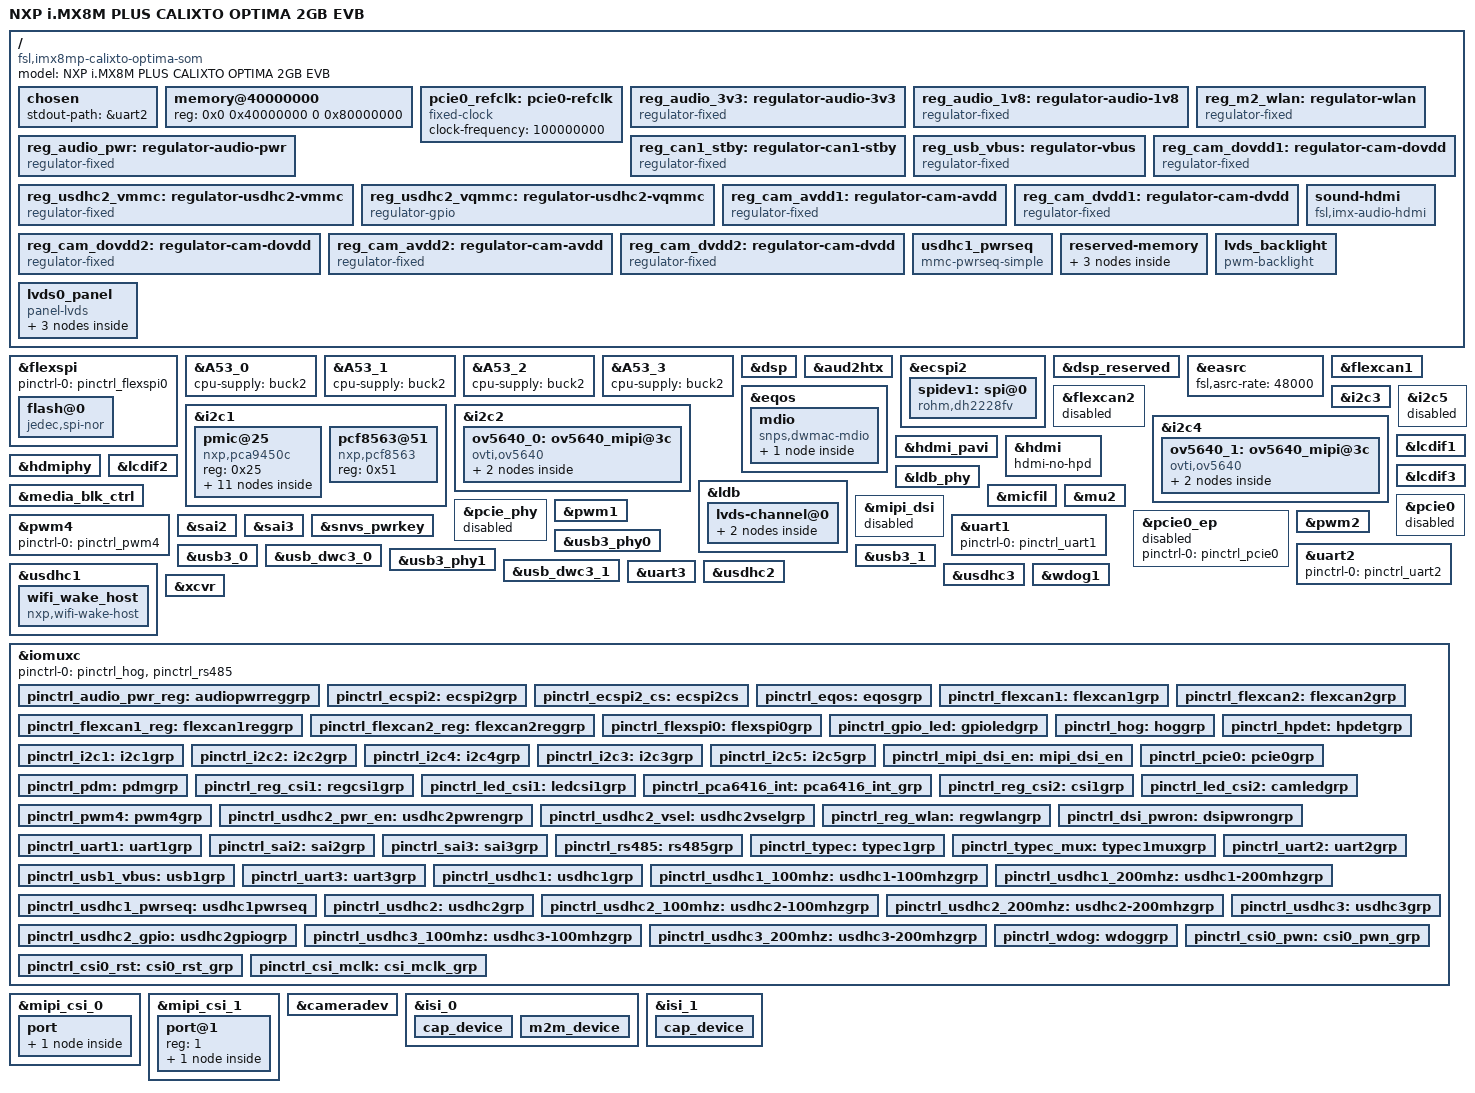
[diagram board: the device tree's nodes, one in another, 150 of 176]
// SPDX-License-Identifier: (GPL-2.0+ OR MIT)
/*
 * Copyright 2019 NXP
 */

/dts-v1/;

#include <dt-bindings/phy/phy-imx8-pcie.h>
#include <dt-bindings/usb/pd.h>
#include "imx8mp.dtsi"
#include "imx8mp-nxp-display.dtsi"
#include "imx8mp-nxp-capture.dtsi"

/ {
	model = "NXP i.MX8M PLUS CALIXTO OPTIMA 2GB EVB";
	compatible = "fsl,imx8mp-calixto-optima-som", "fsl,imx8mp";

	chosen {
		stdout-path = &uart2;
	};

	memory@40000000 {
		device_type = "memory";
		reg = <0x0 0x40000000 0 0x80000000>;
	};

	pcie0_refclk: pcie0-refclk {
		compatible = "fixed-clock";
		#clock-cells = <0>;
		clock-frequency = <100000000>;
	};

	reg_audio_3v3: regulator-audio-3v3 {
		compatible = "regulator-fixed";
		regulator-name = "audio-3v3";
		regulator-min-microvolt = <3300000>;
		regulator-max-microvolt = <3300000>;
		regulator-always-on;
		regulator-boot-on;
	};

	reg_audio_1v8: regulator-audio-1v8 {
		compatible = "regulator-fixed";
		regulator-name = "audio-1v8";
		regulator-min-microvolt = <1800000>;
		regulator-max-microvolt = <1800000>;
		regulator-always-on;
		regulator-boot-on;
	};

	reg_audio_pwr: regulator-audio-pwr {
		compatible = "regulator-fixed";
		regulator-name = "audio-pwr";
		regulator-min-microvolt = <3300000>;
		regulator-max-microvolt = <3300000>;
		regulator-always-on;
		regulator-boot-on;
	};

	reg_can1_stby: regulator-can1-stby {
		compatible = "regulator-fixed";
		regulator-name = "can1-stby";
		regulator-min-microvolt = <3300000>;
		regulator-max-microvolt = <3300000>;
		regulator-always-on;
		regulator-boot-on;
	};

	reg_m2_wlan: regulator-wlan {
		compatible = "regulator-fixed";
		regulator-name = "WLAN_EN";
		regulator-min-microvolt = <3300000>;
		regulator-max-microvolt = <3300000>;
		regulator-always-on;
		regulator-boot-on;
	};

	reg_usb_vbus: regulator-vbus {
		compatible = "regulator-fixed";
		regulator-name = "USB_VBUS";
		regulator-min-microvolt = <5000000>;
		regulator-max-microvolt = <5000000>;
		regulator-always-on;		
		regulator-boot-on;
	};
	
	reg_usdhc2_vmmc: regulator-usdhc2-vmmc {
		compatible = "regulator-fixed";
		pinctrl-names = "default";
		pinctrl-0 = <&pinctrl_usdhc2_pwr_en>;
		gpios = <&gpio2 19 GPIO_ACTIVE_HIGH>;
		enable-active-high;
		off-on-delay-us = <100000>;
		regulator-always-on;
		regulator-max-microvolt = <3300000>;
		regulator-min-microvolt = <3300000>;
		regulator-name = "3V3_SD";
		startup-delay-us = <20000>;
	};

	reg_usdhc2_vqmmc: regulator-usdhc2-vqmmc {
		compatible = "regulator-gpio";
		pinctrl-names = "default";
		pinctrl-0 = <&pinctrl_usdhc2_vsel>;
		gpios = <&gpio1 4 GPIO_ACTIVE_HIGH>;
		regulator-max-microvolt = <3300000>;
		regulator-min-microvolt = <1800000>;
		regulator-always-on;
		states = <1800000 0x1>,
			 <3300000 0x0>;
		regulator-name = "PMIC_USDHC_VSELECT";
		vin-supply = <&ldo5>;
	};
	
	reg_cam_dovdd1: regulator-cam-dovdd {
		compatible = "regulator-fixed";
		pinctrl-names = "default";
		pinctrl-0 = <&pinctrl_reg_csi1>;
		regulator-name = "CAM_DOVDD";
		regulator-min-microvolt = <3000000>;
		regulator-max-microvolt = <3000000>;
		gpio = <&gpio1 3 GPIO_ACTIVE_HIGH>;
		enable-active-high;
	};
	
	reg_cam_avdd1: regulator-cam-avdd {
		compatible = "regulator-fixed";
		regulator-name = "CAM_AVDD";
		regulator-min-microvolt = <2800000>;
		regulator-max-microvolt = <2800000>;
		gpio = <&gpio1 3 GPIO_ACTIVE_HIGH>;
		enable-active-high;
	};
	
	reg_cam_dvdd1: regulator-cam-dvdd {
		compatible = "regulator-fixed";
		regulator-name = "CAM_DVDD";
		regulator-min-microvolt = <1500000>;
		regulator-max-microvolt = <1500000>;
		gpio = <&gpio1 3 GPIO_ACTIVE_HIGH>;
		enable-active-high;
	};

	reg_cam_dovdd2: regulator-cam-dovdd {
		compatible = "regulator-fixed";
		pinctrl-names = "default";
		pinctrl-0 = <&pinctrl_reg_csi1>;
		regulator-name = "CAM_DOVDD";
		regulator-min-microvolt = <3000000>;
		regulator-max-microvolt = <3000000>;
		gpio = <&gpio1 11 GPIO_ACTIVE_HIGH>;
		enable-active-high;
	};
	
	reg_cam_avdd2: regulator-cam-avdd {
		compatible = "regulator-fixed";
		regulator-name = "CAM_AVDD";
		regulator-min-microvolt = <2800000>;
		regulator-max-microvolt = <2800000>;
		gpio = <&gpio1 11 GPIO_ACTIVE_HIGH>;
		enable-active-high;
	};
	
	reg_cam_dvdd2: regulator-cam-dvdd {
		compatible = "regulator-fixed";
		regulator-name = "CAM_DVDD";
		regulator-min-microvolt = <1500000>;
		regulator-max-microvolt = <1500000>;
		gpio = <&gpio1 11 GPIO_ACTIVE_HIGH>;
		enable-active-high;
	};
	
	sound-hdmi {
		compatible = "fsl,imx-audio-hdmi";
		model = "audio-hdmi";
		audio-cpu = <&aud2htx>;
		hdmi-out;
	};

	usdhc1_pwrseq: usdhc1_pwrseq {
		compatible = "mmc-pwrseq-simple";
		pinctrl-names = "default";
		pinctrl-0 = <&pinctrl_usdhc1_pwrseq>;
		reset-gpios = <&gpio2 10 GPIO_ACTIVE_LOW>;
	};

	reserved-memory {
		#address-cells = <2>;
		#size-cells = <2>;
		ranges;

		dsp_vdev0vring0: vdev0vring0@942f0000 {
			reg = <0 0x942f0000 0 0x8000>;
			no-map;
		};

		dsp_vdev0vring1: vdev0vring1@942f8000 {
			reg = <0 0x942f8000 0 0x8000>;
			no-map;
		};

		dsp_vdev0buffer: vdev0buffer@94300000 {
			compatible = "shared-dma-pool";
			reg = <0 0x94300000 0 0x100000>;
			no-map;
		};
	};

	lvds_backlight: lvds_backlight {
		compatible = "pwm-backlight";
		pwms = <&pwm1 0 100000 0>;
		status = "okay";

		brightness-levels = < 0  1  2  3  4  5  6  7  8  9
				     10 11 12 13 14 15 16 17 18 19
				     20 21 22 23 24 25 26 27 28 29
				     30 31 32 33 34 35 36 37 38 39
				     40 41 42 43 44 45 46 47 48 49
				     50 51 52 53 54 55 56 57 58 59
				     60 61 62 63 64 65 66 67 68 69
				     70 71 72 73 74 75 76 77 78 79
				     80 81 82 83 84 85 86 87 88 89
				     90 91 92 93 94 95 96 97 98 99
				    100>;
		default-brightness-level = <80>;
	};
	
	lvds0_panel {
		status = "okay";
		backlight = <&lvds_backlight>;
		compatible = "panel-lvds"; 
		data-mapping = "vesa-24";
		//enable-gpios = <&gpio2 26 GPIO_ACTIVE_HIGH>;
		width-mm = <124>;
		height-mm = <80>;

		panel-timing {
			clock-frequency = <25000000>;
			hactive = <800>;
			vactive = <480>;
			hfront-porch = <8>;
			hback-porch = <8>;
			hsync-len = <4>;
			vback-porch = <8>;
			vfront-porch = <8>;
			vsync-len = <4>;
			hsync-active = <0>;
			vsync-active = <0>;
			de-active = <1>;
                	pixelclk-active = <0>;
		};

		port {
			panel_lvds_in: endpoint {
				remote-endpoint = <&lvds_out>;
			};
		};
	};
	
};

&flexspi {
	pinctrl-names = "default";
	pinctrl-0 = <&pinctrl_flexspi0>;
	status = "okay";

	flash@0 {
		compatible = "jedec,spi-nor";
		reg = <0>;
		spi-max-frequency = <80000000>;
		spi-tx-bus-width = <1>;
		spi-rx-bus-width = <4>;
	};
};

&A53_0 {
	cpu-supply = <&buck2>;
};

&A53_1 {
	cpu-supply = <&buck2>;
};

&A53_2 {
	cpu-supply = <&buck2>;
};

&A53_3 {
	cpu-supply = <&buck2>;
};

&dsp {
	status = "okay";
};

&aud2htx {
	status = "okay";
};

&ecspi2 {
	#address-cells = <1>;
	#size-cells = <0>;
	pinctrl-names = "default";
	pinctrl-0 = <&pinctrl_ecspi2 &pinctrl_ecspi2_cs>;
	cs-gpios = <&gpio5 13 GPIO_ACTIVE_LOW>;
	status = "okay";

	spidev1: spi@0 {
		reg = <0>;
		compatible = "rohm,dh2228fv";
		spi-max-frequency = <500000>;
	};
};

&dsp_reserved {
	status = "okay";
};

&dsp {
	memory-region = <&dsp_vdev0buffer>, <&dsp_vdev0vring0>,
			<&dsp_vdev0vring1>, <&dsp_reserved>;
	status = "okay";
};

&easrc {
	fsl,asrc-rate = <48000>;
	status = "okay";
};

&eqos {
	pinctrl-names = "default";
	pinctrl-0 = <&pinctrl_eqos>;
	phy-mode = "rgmii-id";
	phy-handle = <&ethphy0>;
	status = "okay";

	mdio {
		compatible = "snps,dwmac-mdio";
		#address-cells = <1>;
		#size-cells = <0>;

		ethphy0: ethernet-phy@6 {
			compatible = "ethernet-phy-ieee802.3-c22";
			reg = <6>;
			//reset-gpios = <&gpio4 22 GPIO_ACTIVE_LOW>;
			reset-assert-us = <10000>;
			reset-deassert-us = <80000>;
			//realtek,clkout-disable;
		};
	};

};

&flexcan1 {
	pinctrl-names = "default";
	pinctrl-0 = <&pinctrl_flexcan1>;
	xceiver-supply = <&reg_can1_stby>;
	status = "okay";
};

&flexcan2 {
	status = "disabled";/* can2 pin conflict with pdm */
};

&i2c1 {
	clock-frequency = <400000>;
	pinctrl-names = "default";
	pinctrl-0 = <&pinctrl_i2c1>;
	status = "okay";

	pmic@25 {
		compatible = "nxp,pca9450c";
		reg = <0x25>;

		regulators {
			buck1: BUCK1 {
				regulator-name = "BUCK1";
				regulator-min-microvolt = <600000>;
				regulator-max-microvolt = <2187500>;
				regulator-boot-on;
				regulator-always-on;
				regulator-ramp-delay = <3125>;
			};

			buck2: BUCK2 {
				regulator-name = "BUCK2";
				regulator-min-microvolt = <600000>;
				regulator-max-microvolt = <2187500>;
				regulator-boot-on;
				regulator-always-on;
				regulator-ramp-delay = <3125>;
				nxp,dvs-run-voltage = <950000>;
				nxp,dvs-standby-voltage = <850000>;
			};

			buck4: BUCK4{
				regulator-name = "BUCK4";
				regulator-min-microvolt = <600000>;
				regulator-max-microvolt = <3400000>;
				regulator-boot-on;
				regulator-always-on;
			};

			buck5: BUCK5{
				regulator-name = "BUCK5";
				regulator-min-microvolt = <600000>;
				regulator-max-microvolt = <3400000>;
				regulator-boot-on;
				regulator-always-on;
			};

			buck6: BUCK6 {
				regulator-name = "BUCK6";
				regulator-min-microvolt = <600000>;
				regulator-max-microvolt = <3400000>;
				regulator-boot-on;
				regulator-always-on;
			};

			ldo1: LDO1 {
				regulator-name = "LDO1";
				regulator-min-microvolt = <1600000>;
				regulator-max-microvolt = <3300000>;
				regulator-boot-on;
				regulator-always-on;
			};

			ldo2: LDO2 {
				regulator-name = "LDO2";
				regulator-min-microvolt = <800000>;
				regulator-max-microvolt = <1150000>;
				regulator-boot-on;
				regulator-always-on;
			};

			ldo3: LDO3 {
				regulator-name = "LDO3";
				regulator-min-microvolt = <800000>;
				regulator-max-microvolt = <3300000>;
				regulator-boot-on;
				regulator-always-on;
			};

			ldo4: LDO4 {
				regulator-name = "LDO4";
				regulator-min-microvolt = <800000>;
				regulator-max-microvolt = <3300000>;
				regulator-boot-on;
				regulator-always-on;
			};

			ldo5: LDO5 {
				regulator-name = "LDO5";
				regulator-min-microvolt = <1800000>;
				regulator-max-microvolt = <3300000>;
				regulator-boot-on;
				regulator-always-on;
			};
		};
	};
	
	pcf8563@51 {
		compatible = "nxp,pcf8563";
		reg = <0x51>;
	};
};

&i2c2 {
	clock-frequency = <400000>;
	pinctrl-names = "default";
	pinctrl-0 = <&pinctrl_i2c2>;
	status = "okay";

	ov5640_0: ov5640_mipi@3c {
		compatible = "ovti,ov5640";
		reg = <0x3c>;
		pinctrl-names = "default";
		pinctrl-0 = <&pinctrl_led_csi1>;
		DOVDD-supply = <&reg_cam_dovdd1>; /* 3.0v */
              	AVDD-supply = <&reg_cam_avdd1>;  /* 2.8v */
              	DVDD-supply = <&reg_cam_dvdd1>;  /* 1.5v */
		clocks = <&clk IMX8MP_CLK_IPP_DO_CLKO2>;
		clock-names = "xclk";
		assigned-clocks = <&clk IMX8MP_CLK_IPP_DO_CLKO2>;
		assigned-clock-parents = <&clk IMX8MP_CLK_24M>;
		assigned-clock-rates = <24000000>;
		status = "okay";

		port {
			ov5640_mipi_0_ep: endpoint {
				remote-endpoint = <&mipi_csi0_ep>;
				data-lanes = <1 2>;
				clock-lanes = <0>;
			};
		};
	};

};

&i2c3 {
	clock-frequency = <400000>;
	pinctrl-names = "default";
	pinctrl-0 = <&pinctrl_i2c3>;
	status = "okay";

};

/* I2C on expansion connector J22. */
&i2c5 {
	clock-frequency = <100000>; /* Lower clock speed for external bus. */
	pinctrl-names = "default";
	pinctrl-0 = <&pinctrl_i2c5>;
	status = "disabled"; /* can1 pins conflict with i2c5 */

	/* GPIO 2 of PCA6416 is used to switch between CAN1 and I2C5 functions:
	 *     LOW:  CAN1 (default, pull-down)
	 *     HIGH: I2C5
	 * You need to set it to high to enable I2C5 (for example, add gpio-hog
	 * in pca6416 node).
	 */
};

&i2c4 {

	clock-frequency = <400000>;
	pinctrl-names = "default";
	pinctrl-0 = <&pinctrl_i2c4>;
	status = "okay";

	ov5640_1: ov5640_mipi@3c {
		compatible = "ovti,ov5640";
		reg = <0x3c>;
		pinctrl-names = "default";
		pinctrl-0 = <&pinctrl_led_csi2>;
		DOVDD-supply = <&reg_cam_dovdd2>; /* 3.0v */
              	AVDD-supply = <&reg_cam_avdd2>;  /* 2.8v */
              	DVDD-supply = <&reg_cam_dvdd2>;  /* 1.5v */
		clocks = <&clk IMX8MP_CLK_IPP_DO_CLKO2>;
		clock-names = "xclk";
		assigned-clocks = <&clk IMX8MP_CLK_IPP_DO_CLKO2>;
		assigned-clock-parents = <&clk IMX8MP_CLK_24M>;
		assigned-clock-rates = <24000000>;
		csi_id = <0>;
		mclk = <24000000>;
		mclk_source = <0>;
		mipi_csi;
		status = "okay";

		port {
			ov5640_mipi_1_ep: endpoint {
				remote-endpoint = <&mipi_csi1_ep>;
				data-lanes = <1 2>;
				clock-lanes = <0>;
			};
		};
	};
	
};

&hdmi_pavi {
	status = "okay";
};

&hdmi {
	status = "okay";
	hdmi-no-hpd;
};

&hdmiphy {
	status = "okay";
};

&lcdif1 {
	status = "okay";
};

&lcdif2 {
	status = "okay";
};

&lcdif3 {
	status = "okay";

	thres-low  = <1 2>;             /* (FIFO * 1 / 2) */
	thres-high = <3 4>;             /* (FIFO * 3 / 4) */
};

&ldb {
	status = "okay";
	
	lvds-channel@0 {
		#address-cells = <1>;
		#size-cells = <0>;
		fsl,data-mapping = "spwg";
		fsl,data-width = <24>;
		status = "okay";

		port@1 {
			reg = <1>;
			lvds_out: endpoint {
				remote-endpoint = <&panel_lvds_in>;
			};
		};
	};
};

&ldb_phy {
	status = "okay";
};

&media_blk_ctrl {
       assigned-clock-rates = <500000000>, <200000000>,
                              <0>, <0>, <497700000>; // 71.1MHz
                               //<0>, <0>, <358400000>; // 51.2MHz
                              //<0>, <0>, <454970880>; // 64.9Mhz
};

&micfil {
	#sound-dai-cells = <0>;
	pinctrl-names = "default";
	pinctrl-0 = <&pinctrl_pdm>;
	assigned-clocks = <&clk IMX8MP_CLK_PDM>;
	assigned-clock-parents = <&clk IMX8MP_AUDIO_PLL1_OUT>;
	assigned-clock-rates = <196608000>;
	status = "okay";
};

&mipi_dsi {
	#address-cells = <1>;
	#size-cells = <0>;
	status = "disabled";
};

&mu2 {
	status = "okay";
};

&pcie_phy {
	fsl,refclk-pad-mode = <IMX8_PCIE_REFCLK_PAD_INPUT>;
	clocks = <&pcie0_refclk>;
	clock-names = "ref";
	status = "disabled";
};

&pcie0 {
	pinctrl-names = "default";
	pinctrl-0 = <&pinctrl_pcie0>;
	reset-gpio = <&gpio2 7 GPIO_ACTIVE_LOW>;
	host-wake-gpio = <&gpio5 21 GPIO_ACTIVE_LOW>;
	vpcie-supply = <&reg_m2_wlan>;
	supports-clkreq;
	status = "disabled";
};

&pcie0_ep {
	pinctrl-0 = <&pinctrl_pcie0>;
	pinctrl-names = "default";
	status = "disabled";
};

&pwm1 {
	//pinctrl-names = "default";
	//pinctrl-0 = <&pinctrl_pwm1>;
	status = "okay";
};

&pwm2 {
	//pinctrl-names = "default";
	//pinctrl-0 = <&pinctrl_pwm2>;
	status = "okay";
};

&pwm4 {
	pinctrl-names = "default";
	pinctrl-0 = <&pinctrl_pwm4>;
	status = "okay";
};

&sai2 {
	#sound-dai-cells = <0>;
	pinctrl-names = "default";
	pinctrl-0 = <&pinctrl_sai2>;
	assigned-clocks = <&clk IMX8MP_CLK_SAI2>;
	assigned-clock-parents = <&clk IMX8MP_AUDIO_PLL1_OUT>;
	assigned-clock-rates = <12288000>;
	fsl,sai-mclk-direction-output;
	status = "okay";
};

&sai3 {
	pinctrl-names = "default";
	pinctrl-0 = <&pinctrl_sai3>;
	assigned-clocks = <&clk IMX8MP_CLK_SAI3>;
	assigned-clock-parents = <&clk IMX8MP_AUDIO_PLL1_OUT>;
	assigned-clock-rates = <12288000>;
	fsl,sai-mclk-direction-output;
	status = "okay";
};

&snvs_pwrkey {
	status = "okay";
};

&uart1 { 
	pinctrl-names = "default";
	pinctrl-0 = <&pinctrl_uart1>;
	status = "okay";
};

&uart2 {
	/* console */
	pinctrl-names = "default";
	pinctrl-0 = <&pinctrl_uart2>;
	status = "okay";
};

&usb3_phy0 {
	fsl,phy-tx-vref-tune-percent = <122>;
	fsl,phy-tx-preemp-amp-tune-microamp = <1800>;
	fsl,phy-tx-vboost-level-microvolt = <1156>;
	fsl,phy-comp-dis-tune-percent = <115>;
	fsl,phy-pcs-tx-deemph-3p5db-attenuation-db = <33>;
	fsl,phy-pcs-tx-swing-full-percent = <100>;
	status = "okay";
};

&usb3_0 {
	status = "okay";
};

&usb_dwc3_0 {
	dr_mode = "host";
	hnp-disable;
	srp-disable;
	adp-disable;
	snps,dis-u1-entry-quirk;
	snps,dis-u2-entry-quirk;
	status = "okay";
};

&usb3_phy1 {
	fsl,phy-tx-preemp-amp-tune-microamp = <1800>;
	fsl,phy-tx-vref-tune-percent = <116>;
	status = "okay";
};

&usb3_1 {
	status = "okay";
};

&usb_dwc3_1 {
	vbus-supply = <&reg_usb_vbus>;
	dr_mode = "host";
	status = "okay";
};

&uart3 {
	pinctrl-names = "default";
	pinctrl-0 = <&pinctrl_uart3>;
	assigned-clocks = <&clk IMX8MP_CLK_UART3>;
	assigned-clock-parents = <&clk IMX8MP_SYS_PLL1_80M>;
	uart-has-rtscts;
	status = "okay";
};

&usdhc1 {
	pinctrl-names = "default", "state_100mhz", "state_200mhz";
	pinctrl-0 = <&pinctrl_usdhc1>;
	pinctrl-1 = <&pinctrl_usdhc1_100mhz>;
	pinctrl-2 = <&pinctrl_usdhc1_200mhz>;
	keep-power-in-suspend;
	non-removable;
	wakeup-source;
	mmc-pwrseq = <&usdhc1_pwrseq>;
	vmmc-supply = <&reg_m2_wlan>;
	status = "okay";

	wifi_wake_host {
		compatible = "nxp,wifi-wake-host";
		interrupt-parent = <&gpio2>;
		interrupts = <9 IRQ_TYPE_LEVEL_LOW>;
		interrupt-names = "host-wake";
	};
};

&usdhc2 {
	assigned-clocks = <&clk IMX8MP_CLK_USDHC2>;
	assigned-clock-rates = <400000000>;
	pinctrl-names = "default", "state_100mhz", "state_200mhz";
	pinctrl-0 = <&pinctrl_usdhc2>, <&pinctrl_usdhc2_gpio>;
	pinctrl-1 = <&pinctrl_usdhc2_100mhz>, <&pinctrl_usdhc2_gpio>;
	pinctrl-2 = <&pinctrl_usdhc2_200mhz>, <&pinctrl_usdhc2_gpio>;
	cd-gpios = <&gpio2 12 GPIO_ACTIVE_LOW>;
	vmmc-supply = <&reg_usdhc2_vmmc>;
	vqmmc-supply = <&reg_usdhc2_vqmmc>;
	bus-width = <4>;
	sd-uhs-sdr12;
	sd-uhs-sdr25;
	sd-uhs-sdr50;
	sd-uhs-sdr104;
	no-1-8-v;
	status = "okay";
};

&usdhc3 {
	assigned-clocks = <&clk IMX8MP_CLK_USDHC3>;
	assigned-clock-rates = <400000000>;
	pinctrl-names = "default", "state_100mhz", "state_200mhz";
	pinctrl-0 = <&pinctrl_usdhc3>;
	pinctrl-1 = <&pinctrl_usdhc3_100mhz>;
	pinctrl-2 = <&pinctrl_usdhc3_200mhz>;
	bus-width = <8>;
	non-removable;
	status = "okay";
};

&wdog1 {
	pinctrl-names = "default";
	pinctrl-0 = <&pinctrl_wdog>;
	fsl,ext-reset-output;
	status = "okay";
};

&xcvr {
	#sound-dai-cells = <0>;
	status = "okay";
};

&iomuxc {
	pinctrl-names = "default";
	pinctrl-0 = <&pinctrl_hog &pinctrl_rs485>;

	pinctrl_audio_pwr_reg: audiopwrreggrp {
		fsl,pins = <
			MX8MP_IOMUXC_SAI3_RXC__GPIO4_IO29		0xd6
		>;
	};

	pinctrl_ecspi2: ecspi2grp {
		fsl,pins = <
			MX8MP_IOMUXC_ECSPI2_SCLK__ECSPI2_SCLK		0x82
			MX8MP_IOMUXC_ECSPI2_MOSI__ECSPI2_MOSI		0x82
			MX8MP_IOMUXC_ECSPI2_MISO__ECSPI2_MISO		0x82
		>;
	};

	pinctrl_ecspi2_cs: ecspi2cs {
		fsl,pins = <
			MX8MP_IOMUXC_ECSPI2_SS0__GPIO5_IO13		0x40000
		>;
	};

	/*eth0 pins*/
	pinctrl_eqos: eqosgrp {
		fsl,pins = <
			MX8MP_IOMUXC_ENET_MDC__ENET_QOS_MDC				0x2
			MX8MP_IOMUXC_ENET_MDIO__ENET_QOS_MDIO				0x2
			MX8MP_IOMUXC_ENET_RD0__ENET_QOS_RGMII_RD0			0x90
			MX8MP_IOMUXC_ENET_RD1__ENET_QOS_RGMII_RD1			0x90
			MX8MP_IOMUXC_ENET_RD2__ENET_QOS_RGMII_RD2			0x90
			MX8MP_IOMUXC_ENET_RD3__ENET_QOS_RGMII_RD3			0x90
			MX8MP_IOMUXC_ENET_RXC__CCM_ENET_QOS_CLOCK_GENERATE_RX_CLK	0x90
			MX8MP_IOMUXC_ENET_RX_CTL__ENET_QOS_RGMII_RX_CTL			0x90
			MX8MP_IOMUXC_ENET_TD0__ENET_QOS_RGMII_TD0			0x16
			MX8MP_IOMUXC_ENET_TD1__ENET_QOS_RGMII_TD1			0x16
			MX8MP_IOMUXC_ENET_TD2__ENET_QOS_RGMII_TD2			0x16
			MX8MP_IOMUXC_ENET_TD3__ENET_QOS_RGMII_TD3			0x16
			MX8MP_IOMUXC_ENET_TX_CTL__ENET_QOS_RGMII_TX_CTL			0x16
			MX8MP_IOMUXC_ENET_TXC__CCM_ENET_QOS_CLOCK_GENERATE_TX_CLK	0x16
		>;
	};

	/*CAN INTERFACE*/
	pinctrl_flexcan1: flexcan1grp {
		fsl,pins = <
			//MX8MP_IOMUXC_SPDIF_RX__CAN1_RX          0x154
			//MX8MP_IOMUXC_SPDIF_TX__CAN1_TX          0x154
			MX8MP_IOMUXC_SAI2_RXC__CAN1_TX             0x00000106
                	MX8MP_IOMUXC_SAI2_TXC__CAN1_RX             0x00000106
		>;
	};

	pinctrl_flexcan2: flexcan2grp {
		fsl,pins = <
			MX8MP_IOMUXC_SAI5_MCLK__CAN2_RX         0x154
			MX8MP_IOMUXC_SAI5_RXD3__CAN2_TX         0x154
		>;
	};

	pinctrl_flexcan1_reg: flexcan1reggrp {
		fsl,pins = <
			MX8MP_IOMUXC_SPDIF_EXT_CLK__GPIO5_IO05  0x154   /* CAN1_STBY */
		>;
	};

	pinctrl_flexcan2_reg: flexcan2reggrp {
		fsl,pins = <
			MX8MP_IOMUXC_SAI2_MCLK__GPIO4_IO27      0x154   /* CAN2_STBY */
		>;
	};

	pinctrl_flexspi0: flexspi0grp {
		fsl,pins = <
			MX8MP_IOMUXC_NAND_ALE__FLEXSPI_A_SCLK           0x1c2
			MX8MP_IOMUXC_NAND_CE0_B__FLEXSPI_A_SS0_B        0x82
			MX8MP_IOMUXC_NAND_DATA00__FLEXSPI_A_DATA00      0x82
			MX8MP_IOMUXC_NAND_DATA01__FLEXSPI_A_DATA01      0x82
			MX8MP_IOMUXC_NAND_DATA02__FLEXSPI_A_DATA02      0x82
			MX8MP_IOMUXC_NAND_DATA03__FLEXSPI_A_DATA03      0x82
		>;
	};

	pinctrl_gpio_led: gpioledgrp {
		fsl,pins = <
			MX8MP_IOMUXC_NAND_READY_B__GPIO3_IO16	0x140
		>;
	};

	/*HDMI*/
	pinctrl_hog: hoggrp {
		fsl,pins = <
			MX8MP_IOMUXC_HDMI_DDC_SCL__HDMIMIX_HDMI_SCL	0x400001c2
			MX8MP_IOMUXC_HDMI_DDC_SDA__HDMIMIX_HDMI_SDA	0x400001c2
			MX8MP_IOMUXC_HDMI_HPD__HDMIMIX_HDMI_HPD		0x40000010
			MX8MP_IOMUXC_HDMI_CEC__HDMIMIX_HDMI_CEC		0x40000010

			/*
			 * M.2 pin20 & pin21 need to be set to 11 for 88W9098 to select the
			 * default Reference Clock Frequency
			 */
			MX8MP_IOMUXC_SD1_DATA7__GPIO2_IO09		0x1c4
		>;
	};

	pinctrl_hpdet: hpdetgrp {
		fsl,pins = <
			MX8MP_IOMUXC_SAI3_RXFS__GPIO4_IO28		0xd6
		>;
	};

	pinctrl_i2c1: i2c1grp {
		fsl,pins = <
			MX8MP_IOMUXC_I2C1_SCL__I2C1_SCL		0x400001c2
			MX8MP_IOMUXC_I2C1_SDA__I2C1_SDA		0x400001c2
		>;
	};

	pinctrl_i2c2: i2c2grp {
		fsl,pins = <
			MX8MP_IOMUXC_I2C2_SCL__I2C2_SCL		0x400001c2
			MX8MP_IOMUXC_I2C2_SDA__I2C2_SDA		0x400001c2
		>;
	};
	
	pinctrl_i2c4: i2c4grp {
		fsl,pins = <
			MX8MP_IOMUXC_I2C4_SCL__I2C4_SCL         0x400001c3
			MX8MP_IOMUXC_I2C4_SDA__I2C4_SDA         0x400001c3
            >;  
        };

	pinctrl_i2c3: i2c3grp {
		fsl,pins = <
			MX8MP_IOMUXC_I2C3_SCL__I2C3_SCL		0x400001c2
			MX8MP_IOMUXC_I2C3_SDA__I2C3_SDA		0x400001c2
		>;
	};

	pinctrl_i2c5: i2c5grp {
		fsl,pins = <
			MX8MP_IOMUXC_SPDIF_RX__I2C5_SDA         0x400001c2
			MX8MP_IOMUXC_SPDIF_TX__I2C5_SCL         0x400001c2
		>;
	};

	pinctrl_mipi_dsi_en: mipi_dsi_en {
		fsl,pins = <
			MX8MP_IOMUXC_GPIO1_IO08__GPIO1_IO08	0x16
		>;
	};

	pinctrl_pcie0: pcie0grp {
		fsl,pins = <
	//		MX8MP_IOMUXC_I2C4_SCL__PCIE_CLKREQ_B	0x60 /* open drain, pull up */
			MX8MP_IOMUXC_SD1_DATA5__GPIO2_IO07	0x40
	//		MX8MP_IOMUXC_I2C4_SDA__GPIO5_IO21	0x1c4
		>;
	};

	pinctrl_pdm: pdmgrp {
		fsl,pins = <
			MX8MP_IOMUXC_SAI5_RXC__AUDIOMIX_PDM_CLK		0xd6
			MX8MP_IOMUXC_SAI5_RXD0__AUDIOMIX_PDM_BIT_STREAM00	0xd6
			MX8MP_IOMUXC_SAI5_RXD1__AUDIOMIX_PDM_BIT_STREAM01	0xd6
			MX8MP_IOMUXC_SAI5_RXD2__AUDIOMIX_PDM_BIT_STREAM02	0xd6
			MX8MP_IOMUXC_SAI5_RXD3__AUDIOMIX_PDM_BIT_STREAM03	0xd6
		>;
	};

	pinctrl_reg_csi1: regcsi1grp {
		fsl,pins = <
			MX8MP_IOMUXC_GPIO1_IO03__GPIO1_IO03	0x000001c0
		>;
	};
	
	pinctrl_led_csi1: ledcsi1grp {
    		fsl,pins = <
        		MX8MP_IOMUXC_GPIO1_IO07__GPIO1_IO07    	0x000001c0
    		>;
	};

	pinctrl_pca6416_int: pca6416_int_grp {
		fsl,pins = <
			MX8MP_IOMUXC_GPIO1_IO12__GPIO1_IO12	0x146 /* Input pull-up. */
		>;
	};

	pinctrl_reg_csi2: csi1grp {
		fsl,pins = <
			MX8MP_IOMUXC_GPIO1_IO11__GPIO1_IO11	0x000001c0
		>;
	};
	
	pinctrl_led_csi2: camledgrp {
    		fsl,pins = <
        		MX8MP_IOMUXC_GPIO1_IO01__GPIO1_IO01    	0x000001c0
    		>;
	};

	pinctrl_pwm4: pwm4grp {
		fsl,pins = <
			MX8MP_IOMUXC_SAI5_RXFS__PWM4_OUT	0x116
		>;
	};
	
	pinctrl_usdhc2_pwr_en: usdhc2pwrengrp {
		fsl,pins = <
			MX8MP_IOMUXC_SD2_RESET_B__GPIO2_IO19	0x1c4
		>; 
	};
	
	pinctrl_usdhc2_vsel: usdhc2vselgrp {
		fsl,pins = <
			MX8MP_IOMUXC_GPIO1_IO04__GPIO1_IO04	0x10
		>; 
	};

	pinctrl_reg_wlan: regwlangrp {
		fsl,pins = <
			MX8MP_IOMUXC_SD1_DATA4__GPIO2_IO06	0x140
		>;
	};

	pinctrl_dsi_pwron: dsipwrongrp {
    		fsl,pins = <
        		MX8MP_IOMUXC_GPIO1_IO09__GPIO1_IO09    0x16
   		 >;
	};

	pinctrl_uart1: uart1grp {
		fsl,pins = <
			MX8MP_IOMUXC_UART1_RXD__UART1_DCE_RX	0x140
			MX8MP_IOMUXC_UART1_TXD__UART1_DCE_TX	0x140
			MX8MP_IOMUXC_UART3_RXD__UART1_DCE_CTS	0x140
			MX8MP_IOMUXC_UART3_TXD__UART1_DCE_RTS	0x140
		>;
	};

	pinctrl_sai2: sai2grp {
		fsl,pins = <
		//	MX8MP_IOMUXC_SAI2_TXC__AUDIOMIX_SAI2_TX_BCLK	0xd6
			MX8MP_IOMUXC_SAI2_TXFS__AUDIOMIX_SAI2_TX_SYNC	0xd6
			MX8MP_IOMUXC_SAI2_TXD0__AUDIOMIX_SAI2_TX_DATA00	0xd6
			MX8MP_IOMUXC_SAI2_RXD0__AUDIOMIX_SAI2_RX_DATA00	0xd6
		>;
	};

	pinctrl_sai3: sai3grp {
		fsl,pins = <
			MX8MP_IOMUXC_SAI3_TXFS__AUDIOMIX_SAI3_TX_SYNC	0xd6
			MX8MP_IOMUXC_SAI3_TXC__AUDIOMIX_SAI3_TX_BCLK	0xd6
			MX8MP_IOMUXC_SAI3_RXD__AUDIOMIX_SAI3_RX_DATA00	0xd6
			MX8MP_IOMUXC_SAI3_TXD__AUDIOMIX_SAI3_TX_DATA00	0xd6
		//	MX8MP_IOMUXC_SAI3_MCLK__AUDIOMIX_SAI3_MCLK	0xd6
		>;
	};
	
	pinctrl_rs485: rs485grp {
		fsl,pins = <
                MX8MP_IOMUXC_SAI3_MCLK__GPIO5_IO02         0x00000106
            >;
        };

	pinctrl_typec: typec1grp {
		fsl,pins = <
			MX8MP_IOMUXC_SAI1_TXD7__GPIO4_IO19	0x1c4
		>;
	};

	pinctrl_typec_mux: typec1muxgrp {
		fsl,pins = <
			MX8MP_IOMUXC_SAI1_MCLK__GPIO4_IO20	0x16
		>;
	};

	pinctrl_uart2: uart2grp {
		fsl,pins = <
			MX8MP_IOMUXC_UART2_RXD__UART2_DCE_RX	0x140
			MX8MP_IOMUXC_UART2_TXD__UART2_DCE_TX	0x140
		>;
	};

	pinctrl_usb1_vbus: usb1grp {
		fsl,pins = <
			MX8MP_IOMUXC_GPIO1_IO14__GPIO1_IO14		0x10
		>;
	};

	pinctrl_uart3: uart3grp {
		fsl,pins = <
			MX8MP_IOMUXC_ECSPI1_SCLK__UART3_DCE_RX		0x140
			MX8MP_IOMUXC_ECSPI1_MOSI__UART3_DCE_TX		0x140
			MX8MP_IOMUXC_ECSPI1_SS0__UART3_DCE_RTS		0x140
			MX8MP_IOMUXC_ECSPI1_MISO__UART3_DCE_CTS		0x140
		>;
	};

	pinctrl_usdhc1: usdhc1grp {
		fsl,pins = <
			MX8MP_IOMUXC_SD1_CLK__USDHC1_CLK	0x190
			MX8MP_IOMUXC_SD1_CMD__USDHC1_CMD	0x1d0
			MX8MP_IOMUXC_SD1_DATA0__USDHC1_DATA0	0x1d0
			MX8MP_IOMUXC_SD1_DATA1__USDHC1_DATA1	0x1d0
			MX8MP_IOMUXC_SD1_DATA2__USDHC1_DATA2	0x1d0
			MX8MP_IOMUXC_SD1_DATA3__USDHC1_DATA3	0x1d0
		>;
	};

	pinctrl_usdhc1_100mhz: usdhc1-100mhzgrp {
		fsl,pins = <
			MX8MP_IOMUXC_SD1_CLK__USDHC1_CLK	0x194
			MX8MP_IOMUXC_SD1_CMD__USDHC1_CMD	0x1d4
			MX8MP_IOMUXC_SD1_DATA0__USDHC1_DATA0	0x1d4
			MX8MP_IOMUXC_SD1_DATA1__USDHC1_DATA1	0x1d4
			MX8MP_IOMUXC_SD1_DATA2__USDHC1_DATA2	0x1d4
			MX8MP_IOMUXC_SD1_DATA3__USDHC1_DATA3	0x1d4
		>;
	};

	pinctrl_usdhc1_200mhz: usdhc1-200mhzgrp {
		fsl,pins = <
			MX8MP_IOMUXC_SD1_CLK__USDHC1_CLK	0x196
			MX8MP_IOMUXC_SD1_CMD__USDHC1_CMD	0x1d6
			MX8MP_IOMUXC_SD1_DATA0__USDHC1_DATA0	0x1d6
			MX8MP_IOMUXC_SD1_DATA1__USDHC1_DATA1	0x1d6
			MX8MP_IOMUXC_SD1_DATA2__USDHC1_DATA2	0x1d6
			MX8MP_IOMUXC_SD1_DATA3__USDHC1_DATA3	0x1d6
		>;
	};

	pinctrl_usdhc1_pwrseq: usdhc1pwrseq {
		fsl,pins = <
			MX8MP_IOMUXC_SD1_RESET_B__GPIO2_IO10	0x140
		>;
	};

	pinctrl_usdhc2: usdhc2grp {
		fsl,pins = <
			MX8MP_IOMUXC_SD2_CLK__USDHC2_CLK	0x190
			MX8MP_IOMUXC_SD2_CMD__USDHC2_CMD	0x1d0
			MX8MP_IOMUXC_SD2_DATA0__USDHC2_DATA0	0x1d0
			MX8MP_IOMUXC_SD2_DATA1__USDHC2_DATA1	0x1d0
			MX8MP_IOMUXC_SD2_DATA2__USDHC2_DATA2	0x1d0
			MX8MP_IOMUXC_SD2_DATA3__USDHC2_DATA3	0x1d0
			//MX8MP_IOMUXC_GPIO1_IO04__GPIO1_IO04	0xc0
		>;
	};

	pinctrl_usdhc2_100mhz: usdhc2-100mhzgrp {
		fsl,pins = <
			MX8MP_IOMUXC_SD2_CLK__USDHC2_CLK	0x194
			MX8MP_IOMUXC_SD2_CMD__USDHC2_CMD	0x1d4
			MX8MP_IOMUXC_SD2_DATA0__USDHC2_DATA0	0x1d4
			MX8MP_IOMUXC_SD2_DATA1__USDHC2_DATA1	0x1d4
			MX8MP_IOMUXC_SD2_DATA2__USDHC2_DATA2	0x1d4
			MX8MP_IOMUXC_SD2_DATA3__USDHC2_DATA3	0x1d4
			//MX8MP_IOMUXC_GPIO1_IO04__GPIO1_IO04 0xc0
		>;
	};

	pinctrl_usdhc2_200mhz: usdhc2-200mhzgrp {
		fsl,pins = <
			MX8MP_IOMUXC_SD2_CLK__USDHC2_CLK	0x196
			MX8MP_IOMUXC_SD2_CMD__USDHC2_CMD	0x1d6
			MX8MP_IOMUXC_SD2_DATA0__USDHC2_DATA0	0x1d6
			MX8MP_IOMUXC_SD2_DATA1__USDHC2_DATA1	0x1d6
			MX8MP_IOMUXC_SD2_DATA2__USDHC2_DATA2	0x1d6
			MX8MP_IOMUXC_SD2_DATA3__USDHC2_DATA3	0x1d6
			//MX8MP_IOMUXC_GPIO1_IO04__GPIO1_IO04 0xc0
		>;
	};

	pinctrl_usdhc2_gpio: usdhc2gpiogrp {
		fsl,pins = <
			MX8MP_IOMUXC_SD2_CD_B__GPIO2_IO12	0x1c4
		>;
	};

	pinctrl_usdhc3: usdhc3grp {
		fsl,pins = <
			MX8MP_IOMUXC_NAND_WE_B__USDHC3_CLK	0x190
			MX8MP_IOMUXC_NAND_WP_B__USDHC3_CMD	0x1d0
			MX8MP_IOMUXC_NAND_DATA04__USDHC3_DATA0	0x1d0
			MX8MP_IOMUXC_NAND_DATA05__USDHC3_DATA1	0x1d0
			MX8MP_IOMUXC_NAND_DATA06__USDHC3_DATA2	0x1d0
			MX8MP_IOMUXC_NAND_DATA07__USDHC3_DATA3	0x1d0
			MX8MP_IOMUXC_NAND_RE_B__USDHC3_DATA4	0x1d0
			MX8MP_IOMUXC_NAND_CE2_B__USDHC3_DATA5	0x1d0
			MX8MP_IOMUXC_NAND_CE3_B__USDHC3_DATA6	0x1d0
			MX8MP_IOMUXC_NAND_CLE__USDHC3_DATA7	0x1d0
			MX8MP_IOMUXC_NAND_CE1_B__USDHC3_STROBE	0x190
		>;
	};

	pinctrl_usdhc3_100mhz: usdhc3-100mhzgrp {
		fsl,pins = <
			MX8MP_IOMUXC_NAND_WE_B__USDHC3_CLK	0x194
			MX8MP_IOMUXC_NAND_WP_B__USDHC3_CMD	0x1d4
			MX8MP_IOMUXC_NAND_DATA04__USDHC3_DATA0	0x1d4
			MX8MP_IOMUXC_NAND_DATA05__USDHC3_DATA1	0x1d4
			MX8MP_IOMUXC_NAND_DATA06__USDHC3_DATA2	0x1d4
			MX8MP_IOMUXC_NAND_DATA07__USDHC3_DATA3	0x1d4
			MX8MP_IOMUXC_NAND_RE_B__USDHC3_DATA4	0x1d4
			MX8MP_IOMUXC_NAND_CE2_B__USDHC3_DATA5	0x1d4
			MX8MP_IOMUXC_NAND_CE3_B__USDHC3_DATA6	0x1d4
			MX8MP_IOMUXC_NAND_CLE__USDHC3_DATA7	0x1d4
			MX8MP_IOMUXC_NAND_CE1_B__USDHC3_STROBE	0x194
		>;
	};

	pinctrl_usdhc3_200mhz: usdhc3-200mhzgrp {
		fsl,pins = <
			MX8MP_IOMUXC_NAND_WE_B__USDHC3_CLK	0x196
			MX8MP_IOMUXC_NAND_WP_B__USDHC3_CMD	0x1d6
			MX8MP_IOMUXC_NAND_DATA04__USDHC3_DATA0	0x1d6
			MX8MP_IOMUXC_NAND_DATA05__USDHC3_DATA1	0x1d6
			MX8MP_IOMUXC_NAND_DATA06__USDHC3_DATA2	0x1d6
			MX8MP_IOMUXC_NAND_DATA07__USDHC3_DATA3	0x1d6
			MX8MP_IOMUXC_NAND_RE_B__USDHC3_DATA4	0x1d6
			MX8MP_IOMUXC_NAND_CE2_B__USDHC3_DATA5	0x1d6
			MX8MP_IOMUXC_NAND_CE3_B__USDHC3_DATA6	0x1d6
			MX8MP_IOMUXC_NAND_CLE__USDHC3_DATA7	0x1d6
			MX8MP_IOMUXC_NAND_CE1_B__USDHC3_STROBE	0x196
		>;
	};

	pinctrl_wdog: wdoggrp {
		fsl,pins = <
			MX8MP_IOMUXC_GPIO1_IO02__WDOG1_WDOG_B	0x166
		>;
	};

	pinctrl_csi0_pwn: csi0_pwn_grp {
		fsl,pins = <
			MX8MP_IOMUXC_SD1_STROBE__GPIO2_IO11	0x10
		>;
	};

	pinctrl_csi0_rst: csi0_rst_grp {
		fsl,pins = <
			MX8MP_IOMUXC_GPIO1_IO06__GPIO1_IO06		0x10
		>;
	};

	pinctrl_csi_mclk: csi_mclk_grp {
		fsl,pins = <
			MX8MP_IOMUXC_GPIO1_IO15__CCM_CLKO2	0x50
		>;
	};
};

&mipi_csi_0 {
	status = "okay";

	port {
		mipi_csi0_ep: endpoint {
			remote-endpoint = <&ov5640_mipi_0_ep>;
			data-lanes = <2>;
			csis-hs-settle = <13>;
			csis-clk-settle = <2>;
			csis-wclk;
		};
	};
};

&mipi_csi_1 {
	#address-cells = <1>;
	#size-cells = <0>;
	status = "okay";

	port@1 {
		reg = <1>;
		mipi_csi1_ep: endpoint {
			remote-endpoint = <&ov5640_mipi_1_ep>;
			data-lanes = <2>;
			csis-hs-settle = <13>;
			csis-clk-settle = <2>;
			csis-wclk;
		};
	};
};

&cameradev {
	status = "okay";
};

&isi_0 {
	status = "okay";

	cap_device {
		status = "okay";
	};

	m2m_device {
		status = "okay";
	};
};

&isi_1 {
	status = "okay";

	cap_device {
		status = "okay";
	};
};
